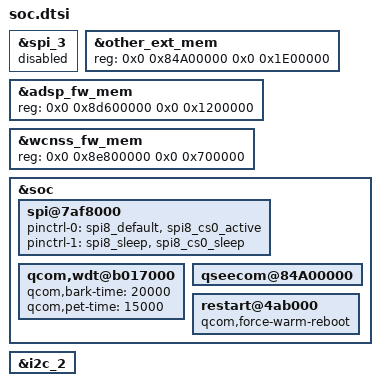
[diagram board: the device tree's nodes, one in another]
/* msm8953-oxygen.dtsi */
&spi_3 {
	status = "disabled";
};

/* msm8953.dtsi */
&other_ext_mem {
	reg = <0x0 0x84A00000 0x0 0x1E00000>;
};
&adsp_fw_mem {
	reg = <0x0 0x8d600000 0x0 0x1200000>;
};
&wcnss_fw_mem {
	reg = <0x0 0x8e800000 0x0 0x700000>;
};
&soc {
	spi@7af8000 { /* BLSP2 QUP4 */
		pinctrl-names = "spi_default", "spi_sleep";
		pinctrl-0 = <&spi8_default &spi8_cs0_active>;
		pinctrl-1 = <&spi8_sleep &spi8_cs0_sleep>;
	};
};
&i2c_2 {
	status = "okay";
	/delete-node/ adv7533@39;
};
&soc {
	qcom,wdt@b017000 {
		qcom,bark-time = <20000>;
		qcom,pet-time = <15000>;
	};
};
&soc {
	/delete-node/ qseecom@85b00000;
	qseecom@84A00000 {
		status = "okay";
	};
};

/* Custom changes */
&soc {
	restart@4ab000 {
		qcom,force-warm-reboot;
	};
};
